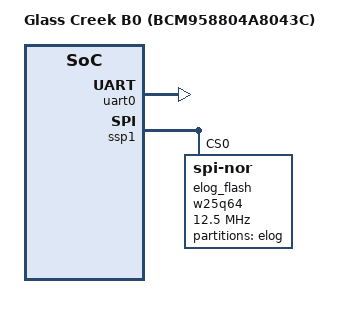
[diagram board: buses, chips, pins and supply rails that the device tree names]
// SPDX-License-Identifier: (GPL-2.0 or BSD-3-Clause)
/*
 *  Copyright(c) 2020 Broadcom
 */

/dts-v1/;

#define NUM_CRYPTO	32
#define NUM_RAID	0
#define ENABLE_ENET	0
#define ENABLE_MDIO	0
#define ENABLE_USB1	0
#define ENABLE_I2C0	1
#define ENABLE_I2C1	0
#define ENABLE_SSP0	0
#define ENABLE_SSP1	0

#ifndef NUM_PAXB
#define NUM_PAXB	3
#define ENABLE_PCIE0	1
#define ENABLE_PCIE1	1
#define ENABLE_PCIE7	1
#endif

#include "stingray-board-base.dtsi"

/ {
	model = "Glass Creek B0 (BCM958804A8043C)";

	chosen {
		stdout-path = "serial1:115200n8";
	};
};

&sdio0 {
	no-1-8-v;
};

&uart0 {
	status = "okay";
};

&ssp1 {
	elog_flash: w25q64@0 {
		#address-cells = <1>;
		#size-cells = <1>;
		compatible = "jedec,spi-nor";
		reg = <0x0>;
		spi-max-frequency = <12500000>;

		partition@0 {
			label = "elog";		/* 8 MiB */
			reg = <0x00000000 0x00800000>;
		};
	};
};
